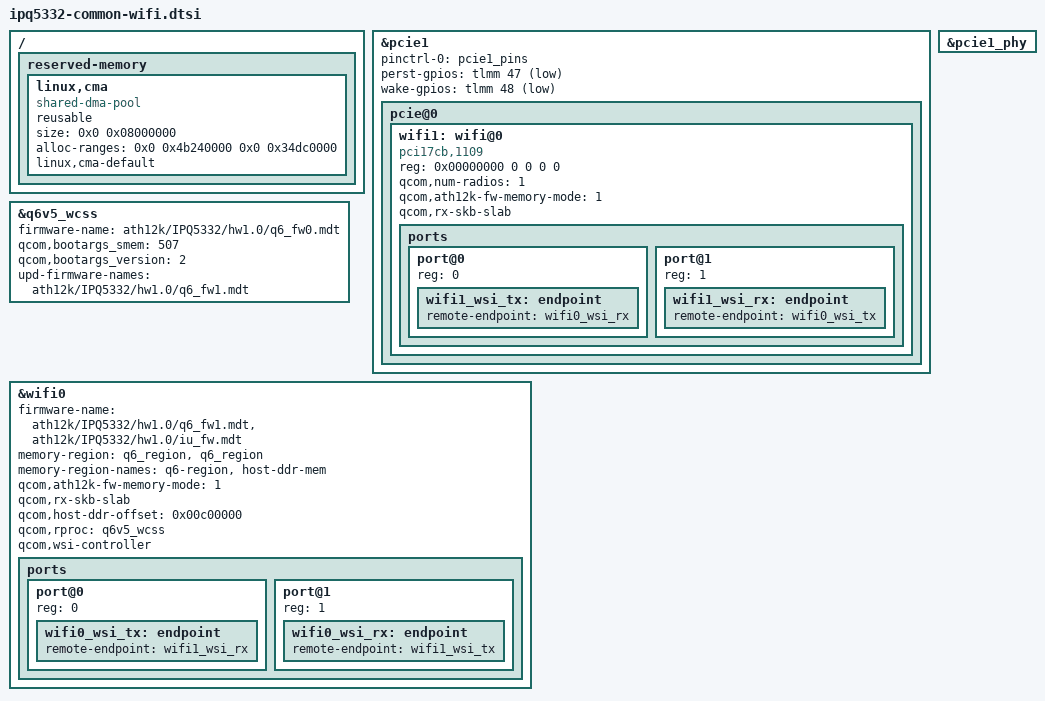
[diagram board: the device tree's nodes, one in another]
// SPDX-License-Identifier: (GPL-2.0+ OR BSD-3-Clause)

/* WCSS/MLO 布局与 VIKINGYFY/immortalwrt target 保持一致：
 * M3 dump、CALDB、MLO 共享池由驱动按需分配，不单独保留；
 * QCN9274（PCI）也不使用固定 host-DDR 保留窗口。
 *
 * Q6 固件（firmware memory mode 1）要求 host DDR 在 0x4b500000 附近由主机
 * 提供 DMA 内存，因此必须给出默认 CMA 池；否则固件镜像缓冲会落到 TZ
 * 不认可的地址，SCM 的 pas_init_image 直接返回 -EIO，Q6 起不来、无 phy。
 */

/ {
	reserved-memory {
		linux,cma {
			compatible = "shared-dma-pool";
			reusable;
			size = <0x0 0x08000000>;
			alloc-ranges = <0x0 0x4b240000 0x0 0x34dc0000>;
			linux,cma-default;
		};
	};
};

&pcie1 {
	status = "okay";

	pinctrl-0 = <&pcie1_pins>;
	pinctrl-names = "default";

	perst-gpios = <&tlmm 47 GPIO_ACTIVE_LOW>;
	wake-gpios = <&tlmm 48 GPIO_ACTIVE_LOW>;

	pcie@0 {
		wifi1: wifi@0 {
			compatible = "pci17cb,1109";
			reg = <0x00000000 0 0 0 0>;
			qcom,num-radios = <1>;
			qcom,ath12k-fw-memory-mode = <1>;
			qcom,rx-skb-slab;

			ports {
				#address-cells = <1>;
				#size-cells = <0>;

				port@0 {
					reg = <0>;

					wifi1_wsi_tx: endpoint {
						remote-endpoint = <&wifi0_wsi_rx>;
					};
				};

				port@1 {
					reg = <1>;

					wifi1_wsi_rx: endpoint {
						remote-endpoint = <&wifi0_wsi_tx>;
					};
				};
			};
		};
	};
};

&pcie1_phy {
	status = "okay";
};

&q6v5_wcss {
	status = "okay";

	firmware-name = "ath12k/IPQ5332/hw1.0/q6_fw0.mdt";
	qcom,bootargs_smem = <507>;
	qcom,bootargs_version = <2>;
	upd-firmware-names = "ath12k/IPQ5332/hw1.0/q6_fw1.mdt";
};

&wifi0 {
	status = "okay";

	firmware-name = "ath12k/IPQ5332/hw1.0/q6_fw1.mdt", "ath12k/IPQ5332/hw1.0/iu_fw.mdt";
	memory-region = <&q6_region>, <&q6_region>;
	memory-region-names = "q6-region", "host-ddr-mem";
	qcom,ath12k-fw-memory-mode = <1>;
	qcom,rx-skb-slab;
	qcom,host-ddr-offset = <0x00c00000>;
	qcom,rproc = <&q6v5_wcss>;
	qcom,wsi-controller;

	ports {
		#address-cells = <1>;
		#size-cells = <0>;

		port@0 {
			reg = <0>;

			wifi0_wsi_tx: endpoint {
				remote-endpoint = <&wifi1_wsi_rx>;
			};
		};

		port@1 {
			reg = <1>;

			wifi0_wsi_rx: endpoint {
				remote-endpoint = <&wifi1_wsi_tx>;
			};
		};
	};
};
